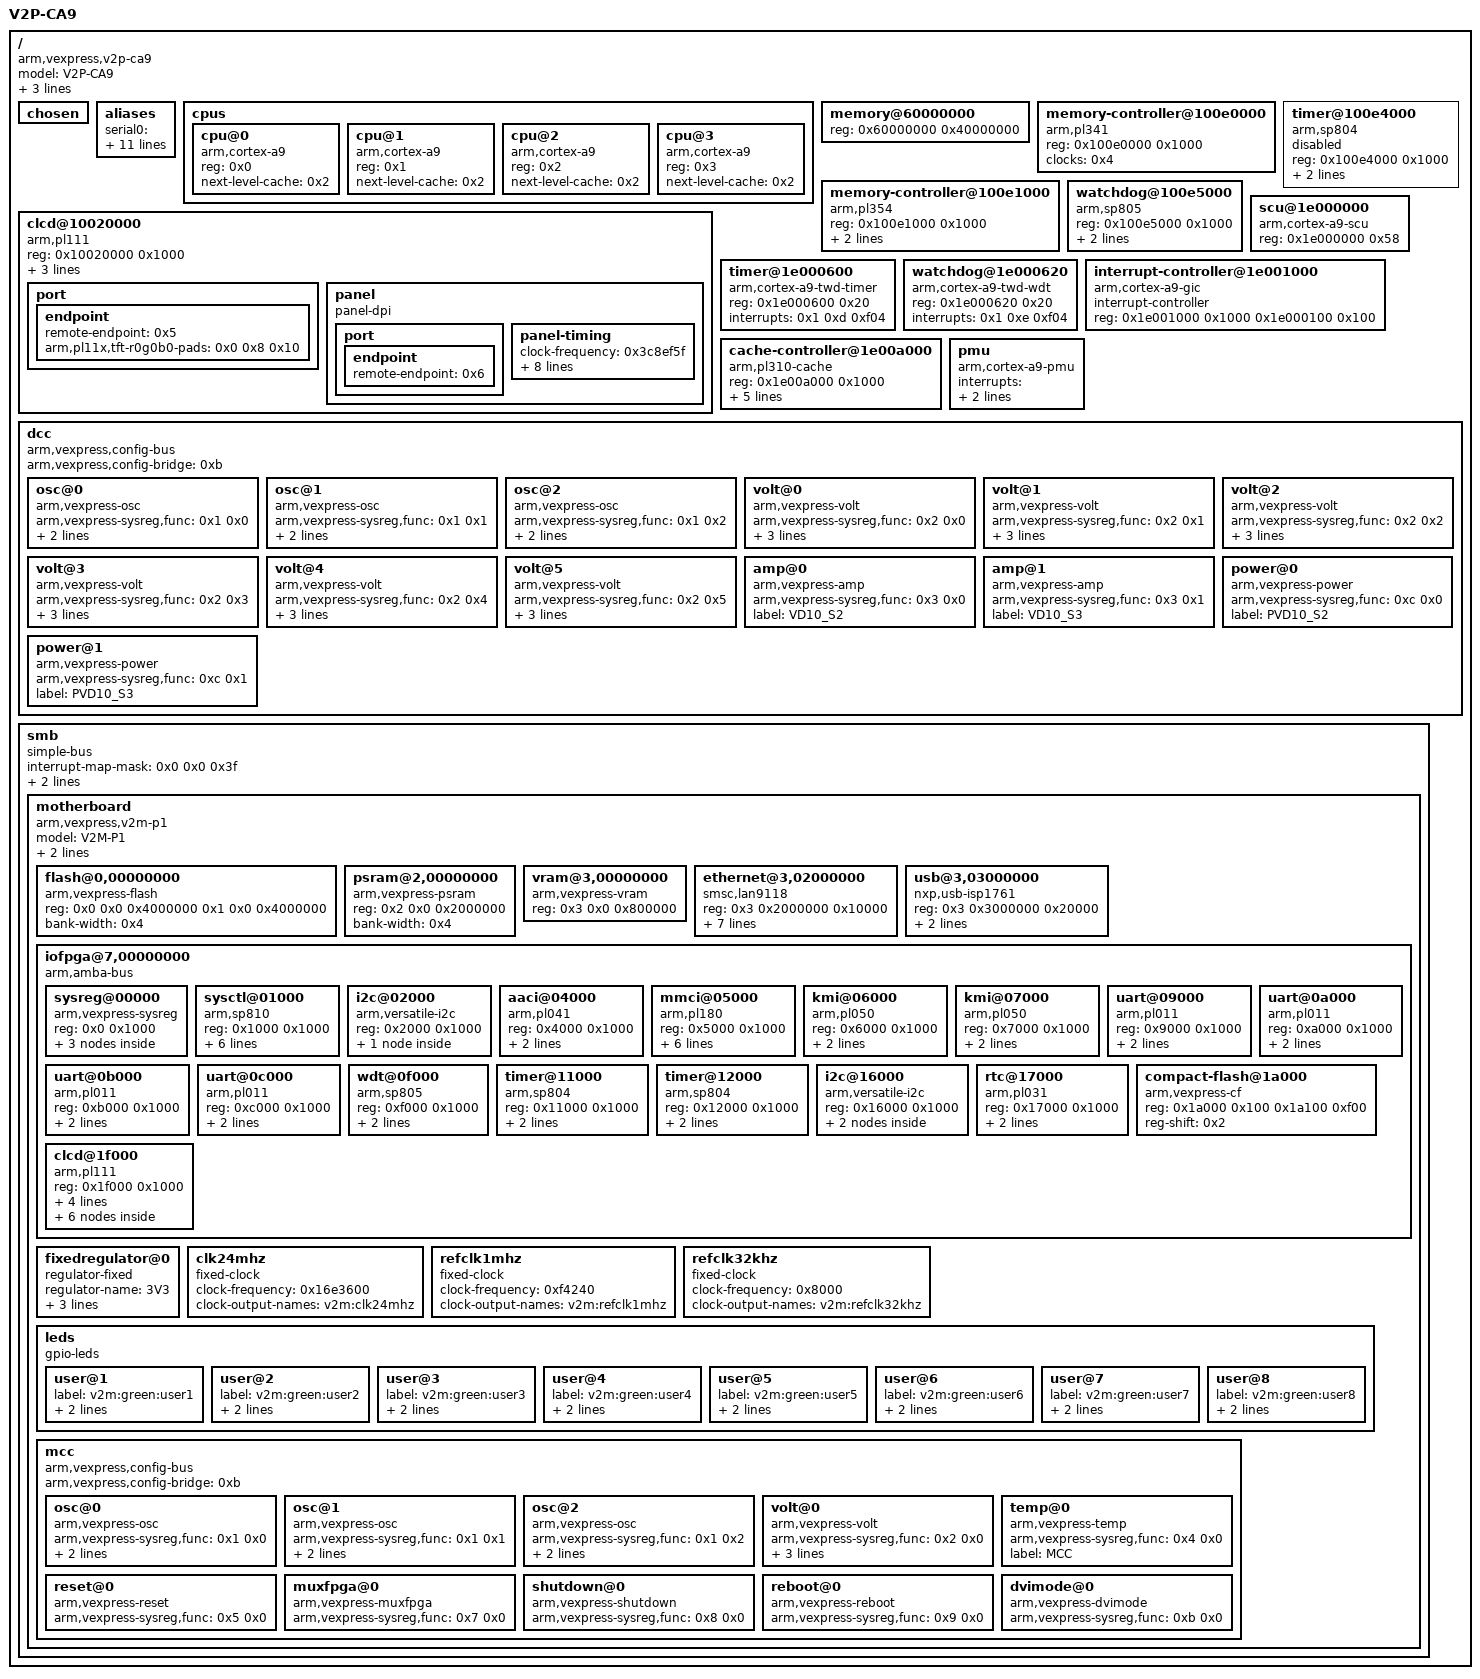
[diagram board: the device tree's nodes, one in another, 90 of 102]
/dts-v1/;

/ {
	model = "V2P-CA9";
	arm,hbi = <0x191>;
	arm,vexpress,site = <0xf>;
	compatible = "arm,vexpress,v2p-ca9", "arm,vexpress";
	interrupt-parent = <0x1>;
	#address-cells = <0x1>;
	#size-cells = <0x1>;

	chosen {
	};

	aliases {
		serial0 = "/smb/motherboard/iofpga@7,00000000/uart@09000";
		serial1 = "/smb/motherboard/iofpga@7,00000000/uart@0a000";
		serial2 = "/smb/motherboard/iofpga@7,00000000/uart@0b000";
		serial3 = "/smb/motherboard/iofpga@7,00000000/uart@0c000";
		i2c0 = "/smb/motherboard/iofpga@7,00000000/i2c@16000";
		i2c1 = "/smb/motherboard/iofpga@7,00000000/i2c@02000";
	};

	cpus {
		#address-cells = <0x1>;
		#size-cells = <0x0>;

		cpu@0 {
			device_type = "cpu";
			compatible = "arm,cortex-a9";
			reg = <0x0>;
			next-level-cache = <0x2>;
			linux,phandle = <0x7>;
			phandle = <0x7>;
		};

		cpu@1 {
			device_type = "cpu";
			compatible = "arm,cortex-a9";
			reg = <0x1>;
			next-level-cache = <0x2>;
			linux,phandle = <0x8>;
			phandle = <0x8>;
		};

		cpu@2 {
			device_type = "cpu";
			compatible = "arm,cortex-a9";
			reg = <0x2>;
			next-level-cache = <0x2>;
			linux,phandle = <0x9>;
			phandle = <0x9>;
		};

		cpu@3 {
			device_type = "cpu";
			compatible = "arm,cortex-a9";
			reg = <0x3>;
			next-level-cache = <0x2>;
			linux,phandle = <0xa>;
			phandle = <0xa>;
		};
	};

	memory@60000000 {
		device_type = "memory";
		reg = <0x60000000 0x40000000>;
	};

	clcd@10020000 {
		compatible = "arm,pl111", "arm,primecell";
		reg = <0x10020000 0x1000>;
		interrupt-names = "combined";
		interrupts = <0x0 0x2c 0x4>;
		clocks = <0x3 0x4>;
		clock-names = "clcdclk", "apb_pclk";
		max-memory-bandwidth = <0x7bfa480>;

		port {

			endpoint {
				remote-endpoint = <0x5>;
				arm,pl11x,tft-r0g0b0-pads = <0x0 0x8 0x10>;
				linux,phandle = <0x6>;
				phandle = <0x6>;
			};
		};

		panel {
			compatible = "panel-dpi";

			port {

				endpoint {
					remote-endpoint = <0x6>;
					linux,phandle = <0x5>;
					phandle = <0x5>;
				};
			};

			panel-timing {
				clock-frequency = <0x3c8ef5f>;
				hactive = <0x400>;
				hback-porch = <0x98>;
				hfront-porch = <0x30>;
				hsync-len = <0x68>;
				vactive = <0x300>;
				vback-porch = <0x17>;
				vfront-porch = <0x3>;
				vsync-len = <0x4>;
			};
		};
	};

	memory-controller@100e0000 {
		compatible = "arm,pl341", "arm,primecell";
		reg = <0x100e0000 0x1000>;
		clocks = <0x4>;
		clock-names = "apb_pclk";
	};

	memory-controller@100e1000 {
		compatible = "arm,pl354", "arm,primecell";
		reg = <0x100e1000 0x1000>;
		interrupts = <0x0 0x2d 0x4 0x0 0x2e 0x4>;
		clocks = <0x4>;
		clock-names = "apb_pclk";
	};

	timer@100e4000 {
		compatible = "arm,sp804", "arm,primecell";
		reg = <0x100e4000 0x1000>;
		interrupts = <0x0 0x30 0x4 0x0 0x31 0x4>;
		clocks = <0x4 0x4>;
		clock-names = "timclk", "apb_pclk";
		status = "disabled";
	};

	watchdog@100e5000 {
		compatible = "arm,sp805", "arm,primecell";
		reg = <0x100e5000 0x1000>;
		interrupts = <0x0 0x33 0x4>;
		clocks = <0x4 0x4>;
		clock-names = "wdogclk", "apb_pclk";
	};

	scu@1e000000 {
		compatible = "arm,cortex-a9-scu";
		reg = <0x1e000000 0x58>;
	};

	timer@1e000600 {
		compatible = "arm,cortex-a9-twd-timer";
		reg = <0x1e000600 0x20>;
		interrupts = <0x1 0xd 0xf04>;
	};

	watchdog@1e000620 {
		compatible = "arm,cortex-a9-twd-wdt";
		reg = <0x1e000620 0x20>;
		interrupts = <0x1 0xe 0xf04>;
	};

	interrupt-controller@1e001000 {
		compatible = "arm,cortex-a9-gic";
		#interrupt-cells = <0x3>;
		#address-cells = <0x0>;
		interrupt-controller;
		reg = <0x1e001000 0x1000 0x1e000100 0x100>;
		linux,phandle = <0x1>;
		phandle = <0x1>;
	};

	cache-controller@1e00a000 {
		compatible = "arm,pl310-cache";
		reg = <0x1e00a000 0x1000>;
		interrupts = <0x0 0x2b 0x4>;
		cache-unified;
		cache-level = <0x2>;
		arm,data-latency = <0x1 0x1 0x1>;
		arm,tag-latency = <0x1 0x1 0x1>;
		linux,phandle = <0x2>;
		phandle = <0x2>;
	};

	pmu {
		compatible = "arm,cortex-a9-pmu";
		interrupts = <0x0 0x3c 0x4 0x0 0x3d 0x4 0x0 0x3e 0x4 0x0 0x3f 0x4>;
		interrupt-affinity = <0x7 0x8 0x9 0xa>;
	};

	dcc {
		compatible = "arm,vexpress,config-bus";
		arm,vexpress,config-bridge = <0xb>;

		osc@0 {
			compatible = "arm,vexpress-osc";
			arm,vexpress-sysreg,func = <0x1 0x0>;
			freq-range = <0x1c9c380 0x2faf080>;
			#clock-cells = <0x0>;
			clock-output-names = "extsaxiclk";
		};

		osc@1 {
			compatible = "arm,vexpress-osc";
			arm,vexpress-sysreg,func = <0x1 0x1>;
			freq-range = <0x989680 0x4c4b400>;
			#clock-cells = <0x0>;
			clock-output-names = "clcdclk";
			linux,phandle = <0x3>;
			phandle = <0x3>;
		};

		osc@2 {
			compatible = "arm,vexpress-osc";
			arm,vexpress-sysreg,func = <0x1 0x2>;
			freq-range = <0x1f78a40 0x5f5e100>;
			#clock-cells = <0x0>;
			clock-output-names = "tcrefclk";
			linux,phandle = <0x4>;
			phandle = <0x4>;
		};

		volt@0 {
			compatible = "arm,vexpress-volt";
			arm,vexpress-sysreg,func = <0x2 0x0>;
			regulator-name = "VD10";
			regulator-always-on;
			label = "VD10";
		};

		volt@1 {
			compatible = "arm,vexpress-volt";
			arm,vexpress-sysreg,func = <0x2 0x1>;
			regulator-name = "VD10_S2";
			regulator-always-on;
			label = "VD10_S2";
		};

		volt@2 {
			compatible = "arm,vexpress-volt";
			arm,vexpress-sysreg,func = <0x2 0x2>;
			regulator-name = "VD10_S3";
			regulator-always-on;
			label = "VD10_S3";
		};

		volt@3 {
			compatible = "arm,vexpress-volt";
			arm,vexpress-sysreg,func = <0x2 0x3>;
			regulator-name = "VCC1V8";
			regulator-always-on;
			label = "VCC1V8";
		};

		volt@4 {
			compatible = "arm,vexpress-volt";
			arm,vexpress-sysreg,func = <0x2 0x4>;
			regulator-name = "DDR2VTT";
			regulator-always-on;
			label = "DDR2VTT";
		};

		volt@5 {
			arm,vexpress-sysreg,func = <0x2 0x5>;
			compatible = "arm,vexpress-volt";
			regulator-name = "VCC3V3";
			regulator-always-on;
			label = "VCC3V3";
		};

		amp@0 {
			compatible = "arm,vexpress-amp";
			arm,vexpress-sysreg,func = <0x3 0x0>;
			label = "VD10_S2";
		};

		amp@1 {
			compatible = "arm,vexpress-amp";
			arm,vexpress-sysreg,func = <0x3 0x1>;
			label = "VD10_S3";
		};

		power@0 {
			compatible = "arm,vexpress-power";
			arm,vexpress-sysreg,func = <0xc 0x0>;
			label = "PVD10_S2";
		};

		power@1 {
			compatible = "arm,vexpress-power";
			arm,vexpress-sysreg,func = <0xc 0x1>;
			label = "PVD10_S3";
		};
	};

	smb {
		compatible = "simple-bus";
		#address-cells = <0x2>;
		#size-cells = <0x1>;
		ranges = <0x0 0x0 0x40000000 0x4000000 0x1 0x0 0x44000000 0x4000000 0x2 0x0 0x48000000 0x4000000 0x3 0x0 0x4c000000 0x4000000 0x7 0x0 0x10000000 0x20000>;
		#interrupt-cells = <0x1>;
		interrupt-map-mask = <0x0 0x0 0x3f>;
		interrupt-map = <0x0 0x0 0x0 0x1 0x0 0x0 0x4 0x0 0x0 0x1 0x1 0x0 0x1 0x4 0x0 0x0 0x2 0x1 0x0 0x2 0x4 0x0 0x0 0x3 0x1 0x0 0x3 0x4 0x0 0x0 0x4 0x1 0x0 0x4 0x4 0x0 0x0 0x5 0x1 0x0 0x5 0x4 0x0 0x0 0x6 0x1 0x0 0x6 0x4 0x0 0x0 0x7 0x1 0x0 0x7 0x4 0x0 0x0 0x8 0x1 0x0 0x8 0x4 0x0 0x0 0x9 0x1 0x0 0x9 0x4 0x0 0x0 0xa 0x1 0x0 0xa 0x4 0x0 0x0 0xb 0x1 0x0 0xb 0x4 0x0 0x0 0xc 0x1 0x0 0xc 0x4 0x0 0x0 0xd 0x1 0x0 0xd 0x4 0x0 0x0 0xe 0x1 0x0 0xe 0x4 0x0 0x0 0xf 0x1 0x0 0xf 0x4 0x0 0x0 0x10 0x1 0x0 0x10 0x4 0x0 0x0 0x11 0x1 0x0 0x11 0x4 0x0 0x0 0x12 0x1 0x0 0x12 0x4 0x0 0x0 0x13 0x1 0x0 0x13 0x4 0x0 0x0 0x14 0x1 0x0 0x14 0x4 0x0 0x0 0x15 0x1 0x0 0x15 0x4 0x0 0x0 0x16 0x1 0x0 0x16 0x4 0x0 0x0 0x17 0x1 0x0 0x17 0x4 0x0 0x0 0x18 0x1 0x0 0x18 0x4 0x0 0x0 0x19 0x1 0x0 0x19 0x4 0x0 0x0 0x1a 0x1 0x0 0x1a 0x4 0x0 0x0 0x1b 0x1 0x0 0x1b 0x4 0x0 0x0 0x1c 0x1 0x0 0x1c 0x4 0x0 0x0 0x1d 0x1 0x0 0x1d 0x4 0x0 0x0 0x1e 0x1 0x0 0x1e 0x4 0x0 0x0 0x1f 0x1 0x0 0x1f 0x4 0x0 0x0 0x20 0x1 0x0 0x20 0x4 0x0 0x0 0x21 0x1 0x0 0x21 0x4 0x0 0x0 0x22 0x1 0x0 0x22 0x4 0x0 0x0 0x23 0x1 0x0 0x23 0x4 0x0 0x0 0x24 0x1 0x0 0x24 0x4 0x0 0x0 0x25 0x1 0x0 0x25 0x4 0x0 0x0 0x26 0x1 0x0 0x26 0x4 0x0 0x0 0x27 0x1 0x0 0x27 0x4 0x0 0x0 0x28 0x1 0x0 0x28 0x4 0x0 0x0 0x29 0x1 0x0 0x29 0x4 0x0 0x0 0x2a 0x1 0x0 0x2a 0x4>;

		motherboard {
			model = "V2M-P1";
			arm,hbi = <0x190>;
			arm,vexpress,site = <0x0>;
			compatible = "arm,vexpress,v2m-p1", "simple-bus";
			#address-cells = <0x2>;
			#size-cells = <0x1>;
			#interrupt-cells = <0x1>;
			ranges;

			flash@0,00000000 {
				compatible = "arm,vexpress-flash", "cfi-flash";
				reg = <0x0 0x0 0x4000000 0x1 0x0 0x4000000>;
				bank-width = <0x4>;
			};

			psram@2,00000000 {
				compatible = "arm,vexpress-psram", "mtd-ram";
				reg = <0x2 0x0 0x2000000>;
				bank-width = <0x4>;
			};

			vram@3,00000000 {
				compatible = "arm,vexpress-vram";
				reg = <0x3 0x0 0x800000>;
				linux,phandle = <0x14>;
				phandle = <0x14>;
			};

			ethernet@3,02000000 {
				compatible = "smsc,lan9118", "smsc,lan9115";
				reg = <0x3 0x2000000 0x10000>;
				interrupts = <0xf>;
				phy-mode = "mii";
				reg-io-width = <0x4>;
				smsc,irq-active-high;
				smsc,irq-push-pull;
				vdd33a-supply = <0xc>;
				vddvario-supply = <0xc>;
			};

			usb@3,03000000 {
				compatible = "nxp,usb-isp1761";
				reg = <0x3 0x3000000 0x20000>;
				interrupts = <0x10>;
				port1-otg;
			};

			iofpga@7,00000000 {
				compatible = "arm,amba-bus", "simple-bus";
				#address-cells = <0x1>;
				#size-cells = <0x1>;
				ranges = <0x0 0x7 0x0 0x20000>;

				sysreg@00000 {
					compatible = "arm,vexpress-sysreg";
					reg = <0x0 0x1000>;
					linux,phandle = <0xb>;
					phandle = <0xb>;

					sys_led@08 {
						compatible = "arm,vexpress-sysreg,sys_led";
						gpio-controller;
						#gpio-cells = <0x2>;
						linux,phandle = <0x17>;
						phandle = <0x17>;
					};

					sys_mci@48 {
						compatible = "arm,vexpress-sysreg,sys_mci";
						gpio-controller;
						#gpio-cells = <0x2>;
						linux,phandle = <0x10>;
						phandle = <0x10>;
					};

					sys_flash@4c {
						compatible = "arm,vexpress-sysreg,sys_flash";
						gpio-controller;
						#gpio-cells = <0x2>;
					};
				};

				sysctl@01000 {
					compatible = "arm,sp810", "arm,primecell";
					reg = <0x1000 0x1000>;
					clocks = <0xd 0xe 0x4>;
					clock-names = "refclk", "timclk", "apb_pclk";
					#clock-cells = <0x1>;
					clock-output-names = "timerclken0", "timerclken1", "timerclken2", "timerclken3";
					assigned-clocks = <0xf 0x0 0xf 0x1 0xf 0x3 0xf 0x3>;
					assigned-clock-parents = <0xe 0xe 0xe 0xe>;
					linux,phandle = <0xf>;
					phandle = <0xf>;
				};

				i2c@02000 {
					compatible = "arm,versatile-i2c";
					reg = <0x2000 0x1000>;
					#address-cells = <0x1>;
					#size-cells = <0x0>;

					pcie-switch@60 {
						compatible = "idt,89hpes32h8";
						reg = <0x60>;
					};
				};

				aaci@04000 {
					compatible = "arm,pl041", "arm,primecell";
					reg = <0x4000 0x1000>;
					interrupts = <0xb>;
					clocks = <0x4>;
					clock-names = "apb_pclk";
				};

				mmci@05000 {
					compatible = "arm,pl180", "arm,primecell";
					reg = <0x5000 0x1000>;
					interrupts = <0x9 0xa>;
					cd-gpios = <0x10 0x0 0x0>;
					wp-gpios = <0x10 0x1 0x0>;
					max-frequency = <0xb71b00>;
					vmmc-supply = <0xc>;
					clocks = <0x11 0x4>;
					clock-names = "mclk", "apb_pclk";
				};

				kmi@06000 {
					compatible = "arm,pl050", "arm,primecell";
					reg = <0x6000 0x1000>;
					interrupts = <0xc>;
					clocks = <0x11 0x4>;
					clock-names = "KMIREFCLK", "apb_pclk";
				};

				kmi@07000 {
					compatible = "arm,pl050", "arm,primecell";
					reg = <0x7000 0x1000>;
					interrupts = <0xd>;
					clocks = <0x11 0x4>;
					clock-names = "KMIREFCLK", "apb_pclk";
				};

				uart@09000 {
					compatible = "arm,pl011", "arm,primecell";
					reg = <0x9000 0x1000>;
					interrupts = <0x5>;
					clocks = <0x12 0x4>;
					clock-names = "uartclk", "apb_pclk";
				};

				uart@0a000 {
					compatible = "arm,pl011", "arm,primecell";
					reg = <0xa000 0x1000>;
					interrupts = <0x6>;
					clocks = <0x12 0x4>;
					clock-names = "uartclk", "apb_pclk";
				};

				uart@0b000 {
					compatible = "arm,pl011", "arm,primecell";
					reg = <0xb000 0x1000>;
					interrupts = <0x7>;
					clocks = <0x12 0x4>;
					clock-names = "uartclk", "apb_pclk";
				};

				uart@0c000 {
					compatible = "arm,pl011", "arm,primecell";
					reg = <0xc000 0x1000>;
					interrupts = <0x8>;
					clocks = <0x12 0x4>;
					clock-names = "uartclk", "apb_pclk";
				};

				wdt@0f000 {
					compatible = "arm,sp805", "arm,primecell";
					reg = <0xf000 0x1000>;
					interrupts = <0x0>;
					clocks = <0xd 0x4>;
					clock-names = "wdogclk", "apb_pclk";
				};

				timer@11000 {
					compatible = "arm,sp804", "arm,primecell";
					reg = <0x11000 0x1000>;
					interrupts = <0x2>;
					clocks = <0xf 0x0 0xf 0x1 0x4>;
					clock-names = "timclken1", "timclken2", "apb_pclk";
				};

				timer@12000 {
					compatible = "arm,sp804", "arm,primecell";
					reg = <0x12000 0x1000>;
					interrupts = <0x3>;
					clocks = <0xf 0x2 0xf 0x3 0x4>;
					clock-names = "timclken1", "timclken2", "apb_pclk";
				};

				i2c@16000 {
					compatible = "arm,versatile-i2c";
					reg = <0x16000 0x1000>;
					#address-cells = <0x1>;
					#size-cells = <0x0>;

					dvi-transmitter@39 {
						compatible = "sil,sii9022-tpi", "sil,sii9022";
						reg = <0x39>;
					};

					dvi-transmitter@60 {
						compatible = "sil,sii9022-cpi", "sil,sii9022";
						reg = <0x60>;
					};
				};

				rtc@17000 {
					compatible = "arm,pl031", "arm,primecell";
					reg = <0x17000 0x1000>;
					interrupts = <0x4>;
					clocks = <0x4>;
					clock-names = "apb_pclk";
				};

				compact-flash@1a000 {
					compatible = "arm,vexpress-cf", "ata-generic";
					reg = <0x1a000 0x100 0x1a100 0xf00>;
					reg-shift = <0x2>;
				};

				clcd@1f000 {
					compatible = "arm,pl111", "arm,primecell";
					reg = <0x1f000 0x1000>;
					interrupt-names = "combined";
					interrupts = <0xe>;
					clocks = <0x13 0x4>;
					clock-names = "clcdclk", "apb_pclk";
					memory-region = <0x14>;
					max-memory-bandwidth = <0x30047b0>;

					port {

						endpoint {
							remote-endpoint = <0x15>;
							arm,pl11x,tft-r0g0b0-pads = <0x0 0x8 0x10>;
							linux,phandle = <0x16>;
							phandle = <0x16>;
						};
					};

					panel {
						compatible = "panel-dpi";

						port {

							endpoint {
								remote-endpoint = <0x16>;
								linux,phandle = <0x15>;
								phandle = <0x15>;
							};
						};

						panel-timing {
							clock-frequency = <0x18023d8>;
							hactive = <0x280>;
							hback-porch = <0x28>;
							hfront-porch = <0x18>;
							hsync-len = <0x60>;
							vactive = <0x1e0>;
							vback-porch = <0x20>;
							vfront-porch = <0xb>;
							vsync-len = <0x2>;
						};
					};
				};
			};

			fixedregulator@0 {
				compatible = "regulator-fixed";
				regulator-name = "3V3";
				regulator-min-microvolt = <0x325aa0>;
				regulator-max-microvolt = <0x325aa0>;
				regulator-always-on;
				linux,phandle = <0xc>;
				phandle = <0xc>;
			};

			clk24mhz {
				compatible = "fixed-clock";
				#clock-cells = <0x0>;
				clock-frequency = <0x16e3600>;
				clock-output-names = "v2m:clk24mhz";
				linux,phandle = <0x11>;
				phandle = <0x11>;
			};

			refclk1mhz {
				compatible = "fixed-clock";
				#clock-cells = <0x0>;
				clock-frequency = <0xf4240>;
				clock-output-names = "v2m:refclk1mhz";
				linux,phandle = <0xe>;
				phandle = <0xe>;
			};

			refclk32khz {
				compatible = "fixed-clock";
				#clock-cells = <0x0>;
				clock-frequency = <0x8000>;
				clock-output-names = "v2m:refclk32khz";
				linux,phandle = <0xd>;
				phandle = <0xd>;
			};

			leds {
				compatible = "gpio-leds";

				user@1 {
					label = "v2m:green:user1";
					gpios = <0x17 0x0 0x0>;
					linux,default-trigger = "heartbeat";
				};

				user@2 {
					label = "v2m:green:user2";
					gpios = <0x17 0x1 0x0>;
					linux,default-trigger = "mmc0";
				};

				user@3 {
					label = "v2m:green:user3";
					gpios = <0x17 0x2 0x0>;
					linux,default-trigger = "cpu0";
				};

				user@4 {
					label = "v2m:green:user4";
					gpios = <0x17 0x3 0x0>;
					linux,default-trigger = "cpu1";
				};

				user@5 {
					label = "v2m:green:user5";
					gpios = <0x17 0x4 0x0>;
					linux,default-trigger = "cpu2";
				};

				user@6 {
					label = "v2m:green:user6";
					gpios = <0x17 0x5 0x0>;
					linux,default-trigger = "cpu3";
				};

				user@7 {
					label = "v2m:green:user7";
					gpios = <0x17 0x6 0x0>;
					linux,default-trigger = "cpu4";
				};

				user@8 {
					label = "v2m:green:user8";
					gpios = <0x17 0x7 0x0>;
					linux,default-trigger = "cpu5";
				};
			};

			mcc {
				compatible = "arm,vexpress,config-bus";
				arm,vexpress,config-bridge = <0xb>;

				osc@0 {
					compatible = "arm,vexpress-osc";
					arm,vexpress-sysreg,func = <0x1 0x0>;
					freq-range = <0x17d7840 0x3938700>;
					#clock-cells = <0x0>;
					clock-output-names = "v2m:oscclk0";
				};

				osc@1 {
					compatible = "arm,vexpress-osc";
					arm,vexpress-sysreg,func = <0x1 0x1>;
					freq-range = <0x16a6570 0x3dfd240>;
					#clock-cells = <0x0>;
					clock-output-names = "v2m:oscclk1";
					linux,phandle = <0x13>;
					phandle = <0x13>;
				};

				osc@2 {
					compatible = "arm,vexpress-osc";
					arm,vexpress-sysreg,func = <0x1 0x2>;
					freq-range = <0x16e3600 0x16e3600>;
					#clock-cells = <0x0>;
					clock-output-names = "v2m:oscclk2";
					linux,phandle = <0x12>;
					phandle = <0x12>;
				};

				volt@0 {
					compatible = "arm,vexpress-volt";
					arm,vexpress-sysreg,func = <0x2 0x0>;
					regulator-name = "VIO";
					regulator-always-on;
					label = "VIO";
				};

				temp@0 {
					compatible = "arm,vexpress-temp";
					arm,vexpress-sysreg,func = <0x4 0x0>;
					label = "MCC";
				};

				reset@0 {
					compatible = "arm,vexpress-reset";
					arm,vexpress-sysreg,func = <0x5 0x0>;
				};

				muxfpga@0 {
					compatible = "arm,vexpress-muxfpga";
					arm,vexpress-sysreg,func = <0x7 0x0>;
				};

				shutdown@0 {
					compatible = "arm,vexpress-shutdown";
					arm,vexpress-sysreg,func = <0x8 0x0>;
				};

				reboot@0 {
					compatible = "arm,vexpress-reboot";
					arm,vexpress-sysreg,func = <0x9 0x0>;
				};

				dvimode@0 {
					compatible = "arm,vexpress-dvimode";
					arm,vexpress-sysreg,func = <0xb 0x0>;
				};
			};
		};
	};
};
